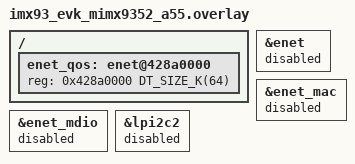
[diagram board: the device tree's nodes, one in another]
/*
 * Copyright 2024-2025 NXP
 *
 * SPDX-License-Identifier: BSD-3-Clause
 */

/ {
	enet_qos: enet@428a0000 {
		reg = <0x428a0000 DT_SIZE_K(64)>;
	};
};

&enet {
	status = "disabled";
};

&enet_mac {
	status = "disabled";
};

&enet_mdio {
	status = "disabled";
};

&lpi2c2 {
	status = "disabled";
};
